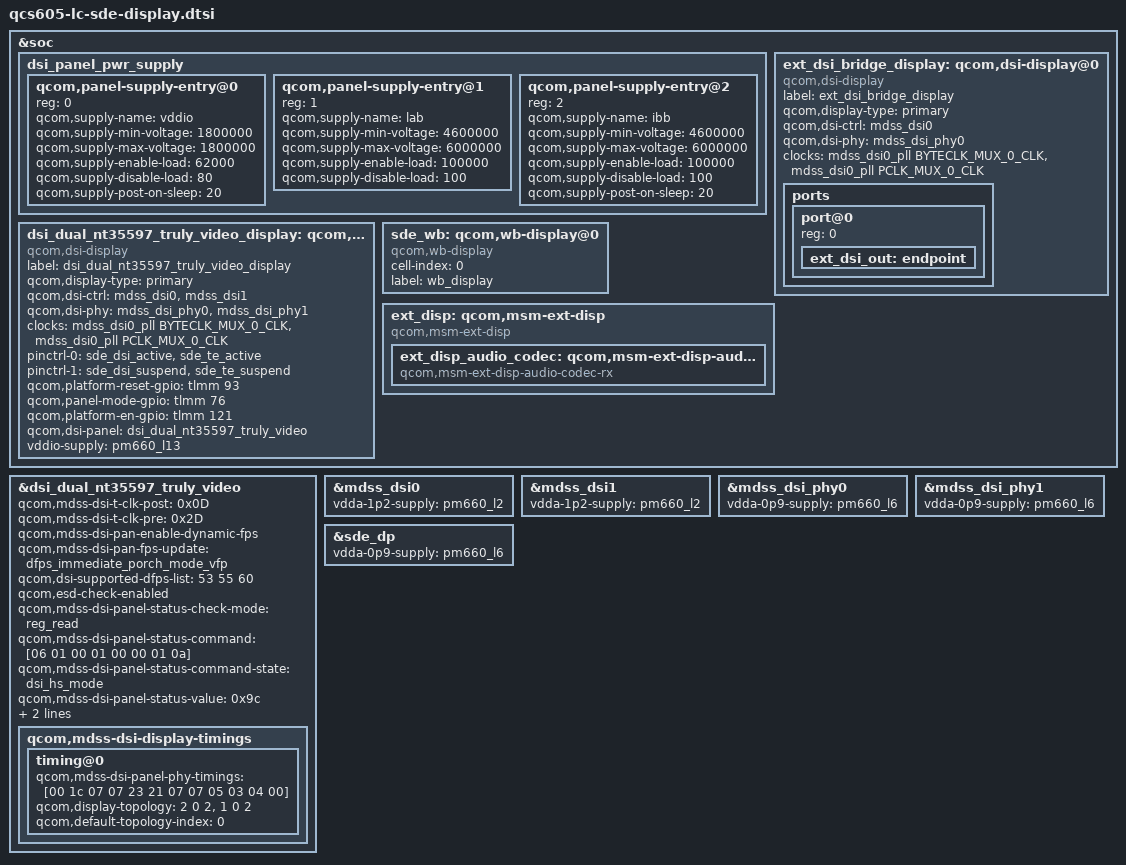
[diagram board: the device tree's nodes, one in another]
/* Copyright (c) 2018, The Linux Foundation. All rights reserved.
 *
 * This program is free software; you can redistribute it and/or modify
 * it under the terms of the GNU General Public License version 2 and
 * only version 2 as published by the Free Software Foundation.
 *
 * This program is distributed in the hope that it will be useful,
 * but WITHOUT ANY WARRANTY; without even the implied warranty of
 * MERCHANTABILITY or FITNESS FOR A PARTICULAR PURPOSE.  See the
 * GNU General Public License for more details.
 */

#include "dsi-panel-nt35597-truly-dualmipi-wqxga-video.dtsi"
#include <dt-bindings/clock/mdss-10nm-pll-clk.h>

&soc {

	dsi_panel_pwr_supply: dsi_panel_pwr_supply {
		#address-cells = <1>;
		#size-cells = <0>;

		qcom,panel-supply-entry@0 {
			reg = <0>;
			qcom,supply-name = "vddio";
			qcom,supply-min-voltage = <1800000>;
			qcom,supply-max-voltage = <1800000>;
			qcom,supply-enable-load = <62000>;
			qcom,supply-disable-load = <80>;
			qcom,supply-post-on-sleep = <20>;
		};

		qcom,panel-supply-entry@1 {
			reg = <1>;
			qcom,supply-name = "lab";
			qcom,supply-min-voltage = <4600000>;
			qcom,supply-max-voltage = <6000000>;
			qcom,supply-enable-load = <100000>;
			qcom,supply-disable-load = <100>;
		};

		qcom,panel-supply-entry@2 {
			reg = <2>;
			qcom,supply-name = "ibb";
			qcom,supply-min-voltage = <4600000>;
			qcom,supply-max-voltage = <6000000>;
			qcom,supply-enable-load = <100000>;
			qcom,supply-disable-load = <100>;
			qcom,supply-post-on-sleep = <20>;
		};
	};

	ext_dsi_bridge_display: qcom,dsi-display@0 {
		compatible = "qcom,dsi-display";
		label = "ext_dsi_bridge_display";
		qcom,display-type = "primary";

		qcom,dsi-ctrl = <&mdss_dsi0>;
		qcom,dsi-phy = <&mdss_dsi_phy0>;
		clocks = <&mdss_dsi0_pll BYTECLK_MUX_0_CLK>,
			<&mdss_dsi0_pll PCLK_MUX_0_CLK>;
		clock-names = "mux_byte_clk", "mux_pixel_clk";

		ports {
			#address-cells = <1>;
			#size-cells = <0>;

			port@0 {
				reg = <0>;
				ext_dsi_out: endpoint {
				};
			};
		};
	};

	dsi_dual_nt35597_truly_video_display: qcom,dsi-display@1 {
		compatible = "qcom,dsi-display";
		label = "dsi_dual_nt35597_truly_video_display";
		qcom,display-type = "primary";

		qcom,dsi-ctrl = <&mdss_dsi0 &mdss_dsi1>;
		qcom,dsi-phy = <&mdss_dsi_phy0 &mdss_dsi_phy1>;
		clocks = <&mdss_dsi0_pll BYTECLK_MUX_0_CLK>,
			<&mdss_dsi0_pll PCLK_MUX_0_CLK>;
		clock-names = "mux_byte_clk", "mux_pixel_clk";

		pinctrl-names = "panel_active", "panel_suspend";
		pinctrl-0 = <&sde_dsi_active &sde_te_active>;
		pinctrl-1 = <&sde_dsi_suspend &sde_te_suspend>;
		qcom,platform-reset-gpio = <&tlmm 93 0>;
		qcom,panel-mode-gpio = <&tlmm 76 0>;
		qcom,platform-en-gpio = <&tlmm 121 0>;

		qcom,dsi-panel = <&dsi_dual_nt35597_truly_video>;
		vddio-supply = <&pm660_l13>;
	};

	sde_wb: qcom,wb-display@0 {
		compatible = "qcom,wb-display";
		cell-index = <0>;
		label = "wb_display";
	};

	ext_disp: qcom,msm-ext-disp {
		compatible = "qcom,msm-ext-disp";

		ext_disp_audio_codec: qcom,msm-ext-disp-audio-codec-rx {
			compatible = "qcom,msm-ext-disp-audio-codec-rx";
		};
	};
};

&dsi_dual_nt35597_truly_video {
	qcom,mdss-dsi-t-clk-post = <0x0D>;
	qcom,mdss-dsi-t-clk-pre = <0x2D>;
	qcom,mdss-dsi-pan-enable-dynamic-fps;
	qcom,mdss-dsi-pan-fps-update =
		"dfps_immediate_porch_mode_vfp";
	qcom,dsi-supported-dfps-list = <53 55 60>;
	qcom,esd-check-enabled;
	qcom,mdss-dsi-panel-status-check-mode = "reg_read";
	qcom,mdss-dsi-panel-status-command = [06 01 00 01 00 00 01 0a];
	qcom,mdss-dsi-panel-status-command-state = "dsi_hs_mode";
	qcom,mdss-dsi-panel-status-value = <0x9c>;
	qcom,mdss-dsi-panel-on-check-value = <0x9c>;
	qcom,mdss-dsi-panel-status-read-length = <1>;
	qcom,mdss-dsi-display-timings {
		timing@0{
			qcom,mdss-dsi-panel-phy-timings = [00 1c 07 07 23 21 07
				07 05 03 04 00];
			qcom,display-topology = <2 0 2>,
						<1 0 2>;
			qcom,default-topology-index = <0>;
		};
	};
};

&mdss_dsi0 {
	vdda-1p2-supply = <&pm660_l2>;
};

&mdss_dsi1 {
	vdda-1p2-supply = <&pm660_l2>;
};

&mdss_dsi_phy0 {
	vdda-0p9-supply = <&pm660_l6>;
};

&mdss_dsi_phy1 {
	vdda-0p9-supply = <&pm660_l6>;
};

&sde_dp {
	vdda-0p9-supply = <&pm660_l6>;
};

